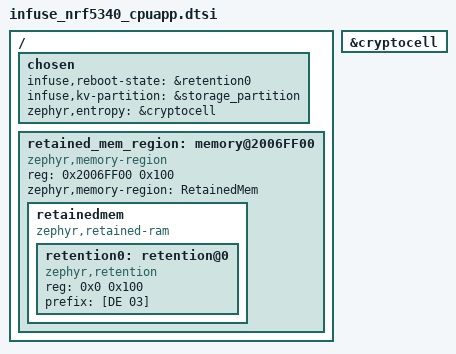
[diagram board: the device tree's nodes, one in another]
/*
 * Copyright (c) 2025 Embeint Holdings Pty Ltd
 * SPDX-License-Identifier: FSL-1.1-ALv2
 */

/ {
	chosen {
		infuse,reboot-state = &retention0;
		infuse,kv-partition = &storage_partition;
	};

	/* End of application SRAM (not in shared SRAM) */
	retained_mem_region: memory@2006FF00 {
		compatible = "zephyr,memory-region", "mmio-sram";
		reg = <0x2006FF00 0x100>;
		zephyr,memory-region = "RetainedMem";
		status = "okay";

		retainedmem {
			compatible = "zephyr,retained-ram";
			status = "okay";
			#address-cells = <1>;
			#size-cells = <1>;

			retention0: retention@0 {
					compatible = "zephyr,retention";
					status = "okay";
					reg = <0x0 0x100>;
					prefix = [DE 03];
			};
		};
	};
};

#ifndef INFUSE_IS_BOOTLOADER

/ {
	chosen {
		zephyr,entropy = &cryptocell;
	};
};

/* Bootloader shouldn't be using cryptocell */
&cryptocell {
	status = "okay";
};

#endif /* !INFUSE_IS_BOOTLOADER */
